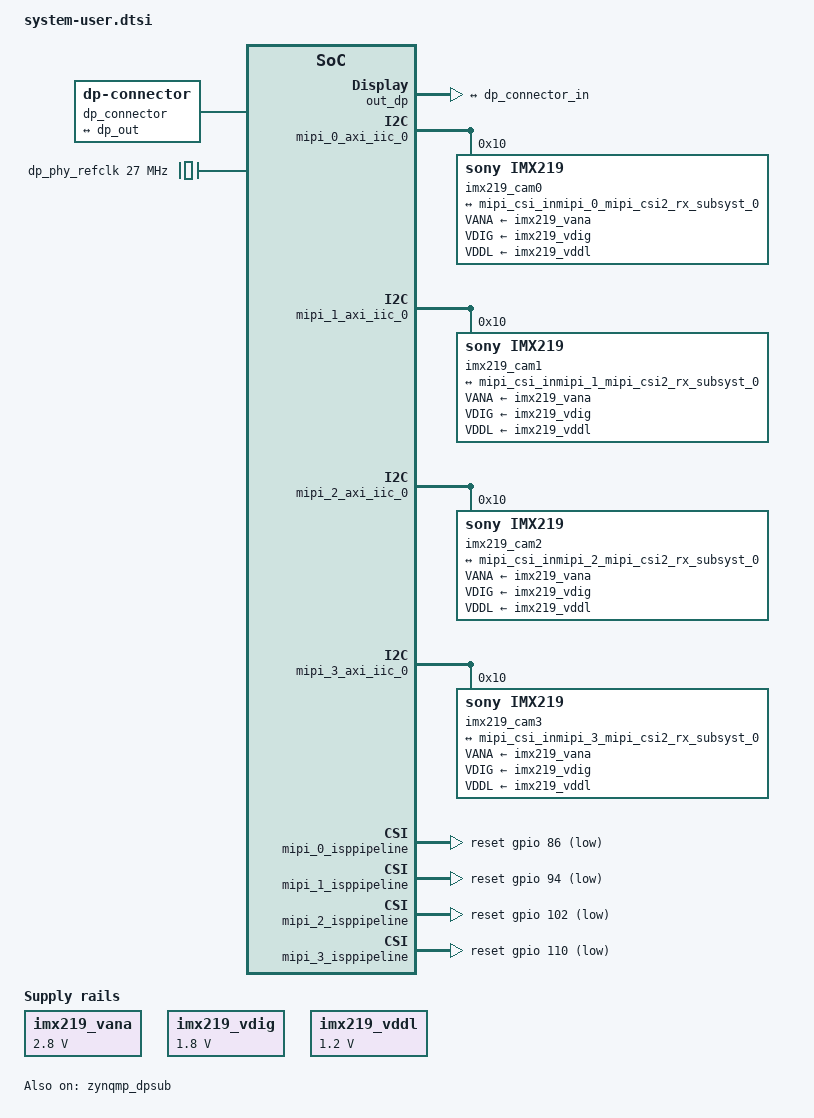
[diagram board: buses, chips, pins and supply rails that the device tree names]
// SPDX-License-Identifier: MIT
// Copyright (C) 2025-2026, Opsero Electronic Design Inc.  All rights reserved.

/*
 * SoC-side board fixups for zcu106 (ZynqMP), layered on top of the
 * gen-machineconf / lopper-generated Linux device tree (which already carries
 * the PS config and the design's PL hardware from the XSA). Scoped to the Linux
 * domain by device-tree.bbappend. Ported from the ZynqMP Hailo AI PetaLinux BSP.
 */

/* From include/dt-bindings/clock/xlnx-zynqmp-clk.h. PetaLinux pulled these in
 * transitively; the EDF device-tree recipe sets KERNEL_INCLUDE="" so they must
 * be inlined here for the DP node's <&zynqmp_clk DP_*_REF> clock refs. */
#define DP_VIDEO_REF 16
#define DP_AUDIO_REF 17

/ {
	dp_aclk: dp_aclk {
		compatible = "fixed-clock";
		#clock-cells = <0>;
		clock-frequency = <100000000>;
		clock-accuracy = <100>;
	};

	/* Repairing misc_clks as per Article number 000036480 */
	/delete-node/ misc_clk_0;
	misc_clk_0: misc_clk_0 {
		#clock-cells = <0>;
		clock-frequency = <99999000>;
		compatible = "fixed-clock";
	};

	/delete-node/ misc_clk_1;
	misc_clk_1: misc_clk_1 {
		#clock-cells = <0>;
		clock-frequency = <249997500>;
		compatible = "fixed-clock";
	};

	/delete-node/ misc_clk_2;
	misc_clk_2: misc_clk_2 {
		#clock-cells = <0>;
		clock-frequency = <199998000>;
		compatible = "fixed-clock";
	};

	/delete-node/ misc_clk_3;
	misc_clk_3: misc_clk_3 {
		#clock-cells = <0>;
		clock-frequency = <49999500>;
		compatible = "fixed-clock";
	};
};

&zynqmp_dpsub {
    status = "okay";
    clocks = <&dp_aclk>,<&zynqmp_clk DP_AUDIO_REF>,<&zynqmp_clk DP_VIDEO_REF>,<&display_pipeline_clk_wiz_0 0>;
    clock-names = "dp_apb_clk", "dp_aud_clk","dp_vtc_pixel_clk_in","dp_live_video_in_clk";
    xlnx,bridge = <&display_pipeline_v_tc_0>;
};

/*
 * 2025.2 zynqmp-dpsub requires endpoints inside the auto-generated
 * &zynqmp_dpsub/ports/port@N children, not as stray port@0 nodes at the
 * dpsub root. Wire live_video (port@0) <-> v_mix CRTC and out_dp (port@5)
 * <-> dp-connector so the driver sees the live-video input and DP output
 * as connected.
 */
&live_video {
    dp_encoder: endpoint {
        remote-endpoint = <&mixer_crtcdisplay_pipeline_v_mix_0>;
    };
};

&out_dp {
    dp_out: endpoint {
        remote-endpoint = <&dp_connector_in>;
    };
};

/ {
    dp_connector: dp-connector {
        compatible = "dp-connector";
        type = "full-size";
        port {
            dp_connector_in: endpoint {
                remote-endpoint = <&dp_out>;
            };
        };
    };

    /*
     * PSGTR ref clock for DP. The auto-generated pcw.dtsi references
     * refclk 3 (xlnx,phys = <&psgtr X 6 X 3>) but doesn't declare any
     * clocks on the psgtr node, so xpsgtr_xlate rejects refclk 3 with
     * "Invalid reference clock number 3" and DP probe fails with -EINVAL.
     * Declare a fixed-clock at 27 MHz (the DP refclk rate FSBL programs
     * the on-board Si5341 to output) so the SSC lookup matches.
     */
    dp_phy_refclk: dp_phy_refclk {
        compatible = "fixed-clock";
        #clock-cells = <0>;
        clock-frequency = <27000000>;
    };
};

&psgtr {
    clocks = <&dp_phy_refclk>;
    clock-names = "ref3";
};

&amba_pl {
	imx219_clk: imx219_clk {
		#clock-cells = <0x0>;
		clock-frequency = <24000000>;
		compatible = "fixed-clock";
	};


	imx219_vana: fixedregulator@3 {
		compatible = "regulator-fixed";
		regulator-name = "imx219_vana";
		regulator-min-microvolt = <2800000>;
		regulator-max-microvolt = <2800000>;
		enable-active-high;
	};

	imx219_vdig: fixedregulator@4 {
		compatible = "regulator-fixed";
		regulator-name = "imx219_vdig";
		regulator-min-microvolt = <1800000>;
		regulator-max-microvolt = <1800000>;
	};

	imx219_vddl: fixedregulator@5 {
		compatible = "regulator-fixed";
		regulator-name = "imx219_vddl";
		regulator-min-microvolt = <1200000>;
		regulator-max-microvolt = <1200000>;
	};
	
};

&mipi_0_axi_iic_0 {
	imx219_cam0: sensor@10 {
		compatible = "sony,imx219";
		reg = <0x10>;
		clocks = <&imx219_clk>;
		VANA-supply = <&imx219_vana>;   /* 2.8v */
		VDIG-supply = <&imx219_vdig>;   /* 1.8v */
		VDDL-supply = <&imx219_vddl>;   /* 1.2v */

		port {
		     imx219_cam0_0: endpoint {
			remote-endpoint = <&mipi_csi_inmipi_0_mipi_csi2_rx_subsyst_0>;
			data-lanes = <1 2>;
			link-frequencies = /bits/ 64 <456000000>;
			};
		};
	};
};

&mipi_1_axi_iic_0 {
	imx219_cam1: sensor@10 {
		compatible = "sony,imx219";
		reg = <0x10>;
		clocks = <&imx219_clk>;
		VANA-supply = <&imx219_vana>;   /* 2.8v */
		VDIG-supply = <&imx219_vdig>;   /* 1.8v */
		VDDL-supply = <&imx219_vddl>;   /* 1.2v */

		port {
		     imx219_cam1_0: endpoint {
			remote-endpoint = <&mipi_csi_inmipi_1_mipi_csi2_rx_subsyst_0>;
			data-lanes = <1 2>;
			link-frequencies = /bits/ 64 <456000000>;
			};
		};
	};
};

&mipi_2_axi_iic_0 {
	imx219_cam2: sensor@10 {
		compatible = "sony,imx219";
		reg = <0x10>;
		clocks = <&imx219_clk>;
		VANA-supply = <&imx219_vana>;   /* 2.8v */
		VDIG-supply = <&imx219_vdig>;   /* 1.8v */
		VDDL-supply = <&imx219_vddl>;   /* 1.2v */

		port {
		     imx219_cam2_0: endpoint {
			remote-endpoint = <&mipi_csi_inmipi_2_mipi_csi2_rx_subsyst_0>;
			data-lanes = <1 2>;
			link-frequencies = /bits/ 64 <456000000>;
			};
		};
	};
};

&mipi_3_axi_iic_0 {
	imx219_cam3: sensor@10 {
		compatible = "sony,imx219";
		reg = <0x10>;
		clocks = <&imx219_clk>;
		VANA-supply = <&imx219_vana>;   /* 2.8v */
		VDIG-supply = <&imx219_vdig>;   /* 1.8v */
		VDDL-supply = <&imx219_vddl>;   /* 1.2v */

		port {
		     imx219_cam3_0: endpoint {
			remote-endpoint = <&mipi_csi_inmipi_3_mipi_csi2_rx_subsyst_0>;
			data-lanes = <1 2>;
			link-frequencies = /bits/ 64 <456000000>;
			};
		};
	};
};

&mipi_0_mipi_csi2_rx_subsyst_0 {
	xlnx,en-active-lanes;
};

&mipi_1_mipi_csi2_rx_subsyst_0 {
	xlnx,en-active-lanes;
};

&mipi_2_mipi_csi2_rx_subsyst_0 {
	xlnx,en-active-lanes;
};

&mipi_3_mipi_csi2_rx_subsyst_0 {
	xlnx,en-active-lanes;
};

&mipi_csi_inmipi_0_mipi_csi2_rx_subsyst_0 {
	remote-endpoint = <&imx219_cam0_0>;
};

&mipi_csi_inmipi_1_mipi_csi2_rx_subsyst_0 {
	remote-endpoint = <&imx219_cam1_0>;
};

&mipi_csi_inmipi_2_mipi_csi2_rx_subsyst_0 {
	remote-endpoint = <&imx219_cam2_0>;
};

&mipi_csi_inmipi_3_mipi_csi2_rx_subsyst_0 {
	remote-endpoint = <&imx219_cam3_0>;
};

&mipi_0_isppipeline {
	reset-gpios = <&gpio 86 1>;
	xlnx,max-height = /bits/ 16 <1232>;
	xlnx,max-width = /bits/ 16 <1920>;
	xlnx,rgain = /bits/ 16 <128>;
	xlnx,bgain = /bits/ 16 <210>;
	xlnx,pawb = /bits/ 16 <350>;
	xlnx,mode-reg = <1>;
};

&isppipeline_port0mipi_0_isppipeline {
	xlnx,video-width = <10>;
	xlnx,cfa-pattern = "rggb";
};

&isppipeline_port1mipi_0_isppipeline {
	xlnx,video-width = <8>;
	xlnx,cfa-pattern = "rggb";
};

&mipi_1_isppipeline {
	reset-gpios = <&gpio 94 1>;
	xlnx,max-height = /bits/ 16 <1232>;
	xlnx,max-width = /bits/ 16 <1920>;
	xlnx,rgain = /bits/ 16 <128>;
	xlnx,bgain = /bits/ 16 <210>;
	xlnx,pawb = /bits/ 16 <350>;
	xlnx,mode-reg = <1>;
};

&isppipeline_port0mipi_1_isppipeline {
	xlnx,video-width = <10>;
	xlnx,cfa-pattern = "rggb";
};

&isppipeline_port1mipi_1_isppipeline {
	xlnx,video-width = <8>;
	xlnx,cfa-pattern = "rggb";
};

&mipi_2_isppipeline {
	reset-gpios = <&gpio 102 1>;
	xlnx,max-height = /bits/ 16 <1232>;
	xlnx,max-width = /bits/ 16 <1920>;
	xlnx,rgain = /bits/ 16 <128>;
	xlnx,bgain = /bits/ 16 <210>;
	xlnx,pawb = /bits/ 16 <350>;
	xlnx,mode-reg = <1>;
};

&isppipeline_port0mipi_2_isppipeline {
	xlnx,video-width = <10>;
	xlnx,cfa-pattern = "rggb";
};

&isppipeline_port1mipi_2_isppipeline {
	xlnx,video-width = <8>;
	xlnx,cfa-pattern = "rggb";
};

&mipi_3_isppipeline {
	reset-gpios = <&gpio 110 1>;
	xlnx,max-height = /bits/ 16 <1232>;
	xlnx,max-width = /bits/ 16 <1920>;
	xlnx,rgain = /bits/ 16 <128>;
	xlnx,bgain = /bits/ 16 <210>;
	xlnx,pawb = /bits/ 16 <350>;
	xlnx,mode-reg = <1>;
};

&isppipeline_port0mipi_3_isppipeline {
	xlnx,video-width = <10>;
	xlnx,cfa-pattern = "rggb";
};

&isppipeline_port1mipi_3_isppipeline {
	xlnx,video-width = <8>;
	xlnx,cfa-pattern = "rggb";
};

&mipi_0_v_proc {
	compatible = "xlnx,v-vpss-scaler-2.2";
};

&mipi_1_v_proc {
	compatible = "xlnx,v-vpss-scaler-2.2";
};

&mipi_2_v_proc {
	compatible = "xlnx,v-vpss-scaler-2.2";
};

&mipi_3_v_proc {
	compatible = "xlnx,v-vpss-scaler-2.2";
};

&display_pipeline_clk_wiz_0 {
	#address-cells = <2>;
};

&mixer_crtcdisplay_pipeline_v_mix_0 {
	remote-endpoint = <&dp_encoder>;
};

&display_pipeline_v_mix_0 {
	xlnx,disp-bridge = <&zynqmp_dpsub>;
	/* 2025.2 xlnx-mixer driver requires xlnx,bridge (VTC timing bridge)
	 * and xlnx,video-format (0=RGB, 1=YUV444, 2=YUV422) on the v_mix
	 * node, otherwise probe fails. Primary layer is NV16, so output is
	 * YUV422. */
	xlnx,bridge = <&display_pipeline_v_tc_0>;
	xlnx,video-format = <2>;
};

&display_pipeline_v_tc_0 {
	compatible = "xlnx,bridge-v-tc-6.1";
	xlnx,pixels-per-clock = <1>;
};

&mipi_csi_port1mipi_0_mipi_csi2_rx_subsyst_0 {
	xlnx,cfa-pattern = "rggb";
	xlnx,video-format = <12>;
	xlnx,video-width = <8>;
};

&mipi_csi_port0mipi_0_mipi_csi2_rx_subsyst_0 {
	xlnx,cfa-pattern = "rggb";
	xlnx,video-format = <12>;
	xlnx,video-width = <8>;
};

&mipi_csi_port1mipi_1_mipi_csi2_rx_subsyst_0 {
	xlnx,cfa-pattern = "rggb";
	xlnx,video-format = <12>;
	xlnx,video-width = <8>;
};

&mipi_csi_port0mipi_1_mipi_csi2_rx_subsyst_0 {
	xlnx,cfa-pattern = "rggb";
	xlnx,video-format = <12>;
	xlnx,video-width = <8>;
};

&mipi_csi_port1mipi_2_mipi_csi2_rx_subsyst_0 {
	xlnx,cfa-pattern = "rggb";
	xlnx,video-format = <12>;
	xlnx,video-width = <8>;
};

&mipi_csi_port0mipi_2_mipi_csi2_rx_subsyst_0 {
	xlnx,cfa-pattern = "rggb";
	xlnx,video-format = <12>;
	xlnx,video-width = <8>;
};

&mipi_csi_port1mipi_3_mipi_csi2_rx_subsyst_0 {
	xlnx,cfa-pattern = "rggb";
	xlnx,video-format = <12>;
	xlnx,video-width = <8>;
};

&mipi_csi_port0mipi_3_mipi_csi2_rx_subsyst_0 {
	xlnx,cfa-pattern = "rggb";
	xlnx,video-format = <12>;
	xlnx,video-width = <8>;
};


/* 2025.2 gen-machineconf assigns port-number=0 to uart1, making ttyPS0 map
 * to uart1. Vitis bsp.yaml confirms this board uses psu_uart_0, so force
 * ttyPS0 back to uart0. */
&uart0 {
   port-number = <0>;
};
&uart1 {
   port-number = <1>;
};
/ {
   aliases {
      serial0 = &uart0;
      serial1 = &uart1;
   };
   chosen {
      stdout-path = "serial0:115200n8";
   };
};
